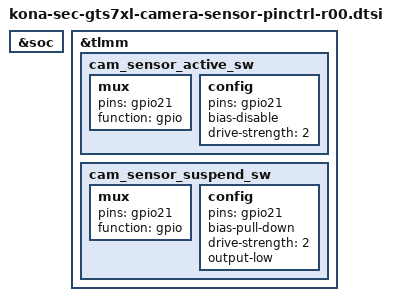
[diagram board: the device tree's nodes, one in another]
/* Copyright (c) 2016-2017, The Linux Foundation. All rights reserved.
 *
 * This program is free software; you can redistribute it and/or modify
 * it under the terms of the GNU General Public License version 2 and
 * only version 2 as published by the Free Software Foundation.
 *
 * This program is distributed in the hope that it will be useful,
 * but WITHOUT ANY WARRANTY; without even the implied warranty of
 * MERCHANTABILITY or FITNESS FOR A PARTICULAR PURPOSE.  See the
 * GNU General Public License for more details.
 */

#include "kona-sec-gts7xl-camera-sensor-pinctrl-common.dtsi"

&soc {
	/* tlmm: pinctrl@03400000 { }; */
};

&tlmm {
	cam_sensor_active_sw: cam_sensor_active_sw {
		/* RESET SW */
		mux {
			pins = "gpio21";
			function = "gpio";
		};

		config {
			pins = "gpio21";
			bias-disable; /* No PULL */
			drive-strength = <2>; /* 2 MA */
		};
	};

	cam_sensor_suspend_sw: cam_sensor_suspend_sw {
		/* RESET SW */
		mux {
			pins = "gpio21";
			function = "gpio";
		};

		config {
			pins = "gpio21";
			bias-pull-down; /* PULL DOWN */
			drive-strength = <2>; /* 2 MA */
			output-low;
		};
	};

};
